# mcr_me14 register map
Registers are access not given, no defined reset value unless marked. A register's access mark holds for its fields unless they carry their own. Offsets are from the block's base; lines under a group give offsets from that group; [hi:lo] are bit positions; {n}, {i} and the like mark numbered series; 'fields as' and 'values as' point back to an identical list; <NAME> marks a mode.

## Memory map
0x40006C00 MCR size 0x400 — Misc Control.

## MCR — Misc Control.
Base 0x40006C00
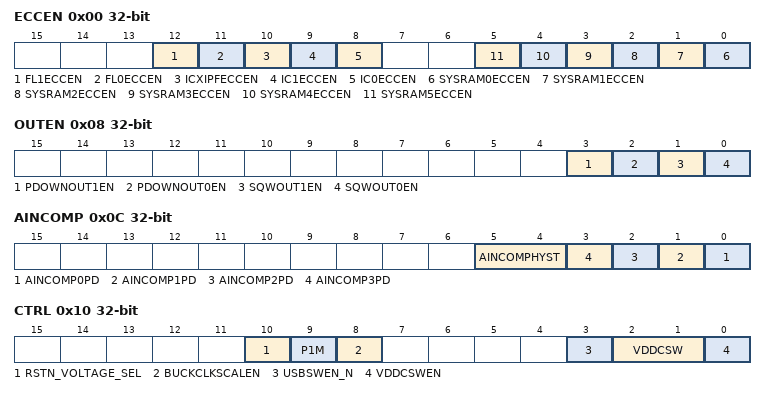
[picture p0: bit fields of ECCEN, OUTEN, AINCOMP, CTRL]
0x00 ECCEN — ECC Enable Register
  [all] fields
    0=dis (disabled.); 1=en (enabled.)
  [12] FL1ECCEN — Flash1 ECC Enable.
  [11] FL0ECCEN — Flash0 ECC Enable.
  [10] ICXIPFECCEN — IcacheXIP ECC Enable.
  [9] IC1ECCEN — Icache1 ECC Enable.
  [8] IC0ECCEN — Icache0 ECC Enable.
  [n] SYSRAM{n}ECCEN (n=0..5) — ECC System RAM Enable.
0x04 HIRC96M — 96MHz High Frequency Clock Adjustment Register
  [8:0] HIRC96MTR — HIRC96M Trim: Allow user to change 96M Frequency
    0x100=Default setting
0x08 OUTEN — GPIOOUT_EN Function Enable Register
  [all] fields
    0=dis (disabled.); 1=en (enabled.)
  [3] PDOWNOUT1EN — Allows PDOWN on GPIO0_26
  [2] PDOWNOUT0EN — Allows PDOWN on GPIO0_18
  [1] SQWOUT1EN — Allows SQWOUT on GPIO0_27
  [0] SQWOUT0EN — Allows SQWOUT on GPIO0_19
0x0C AINCOMP — Comparator Power Control Register
  [5:4] AINCOMPHYST — Set Hysteresis on Analog Comparators
  [n] AINCOMP{n}PD (n=0..3) — Power Down AIN Comp{n}
    0=on (power on); 1=off (power off)
0x10 CTRL — Misc Power State Control Register
  [10] RSTN_VOLTAGE_SEL — Error! Description not Found!
  [9] P1M — Enable the Reset Pad Pull Up Resistors
    0=1m (1MOhm Pullup); 1=25k (25kOhm Pullup.)
  [8] BUCKCLKSCALEN — Allows Dynamic scaling of SIMO clock, reduces power in LP Modes
    0=dis (disabled.); 1=en (enabled.)
  [3] USBSWEN_N — USB Switch Control
    1=off (USB SW off in LP modes); 0=on (USB SW On)
  [2:1] VDDCSW — Controls switching of VCORE
  [0] VDDCSWEN — Allows switching VDDC from VCOREA to VCOREB
    0=dis (disabled.); 1=en (enabled.)
